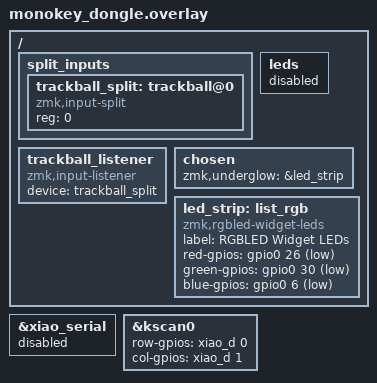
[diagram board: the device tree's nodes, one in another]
#include "monokey.dtsi"

&xiao_serial { status = "disabled"; };

&kscan0 {
    row-gpios = <&xiao_d 0 (GPIO_ACTIVE_HIGH | GPIO_PULL_DOWN)>;
    col-gpios = <&xiao_d 1 GPIO_ACTIVE_HIGH>;
};

/ {

/* 1. ドングル側の「受信機」：右手から送られてくる0番のトラックボールデータを受け取る箱 */
    split_inputs {
        #address-cells = <1>;
        #size-cells = <0>;

        trackball_split: trackball@0 {
            compatible = "zmk,input-split";
            reg = <0>;
            /* ※ドングルには物理センサーが付いていないので、device = <&trackball>; は書きません */
        };
    };

    /* 2. ドングル側の「翻訳係」：受信機に入ったデータを、PCのマウスの動きとして出力する */
    trackball_listener {
        compatible = "zmk,input-listener";
        device = <&trackball_split>;
    };


    /* 1. 標準のLED機能を無効化（ピンの奪い合いによる自爆を防ぐため） */
    leds {
        status = "disabled";
    };

    /* 2. RGBLEDウィジェットを使う宣言 */
    chosen {
        zmk,underglow = &led_strip;
    };

    /* 3. XIAO BLEの物理RGBピンをウィジェットに割り当て */
    led_strip: list_rgb {
        compatible = "zmk,rgbled-widget-leds";
        label = "RGBLED Widget LEDs";
        red-gpios   = <&gpio0 26 GPIO_ACTIVE_LOW>;
        green-gpios = <&gpio0 30 GPIO_ACTIVE_LOW>;
        blue-gpios  = <&gpio0 6  GPIO_ACTIVE_LOW>;
    };

};
